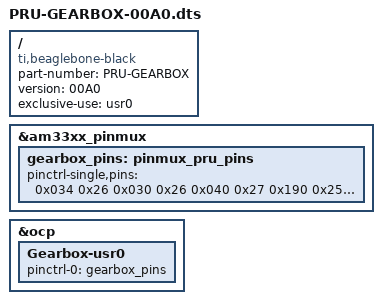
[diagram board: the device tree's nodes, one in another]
 /dts-v1/;  
 /plugin/;  
 
 / {  
   compatible = "ti,beaglebone-black";  
   part-number = "PRU-GEARBOX";  
   version = "00A0";
   exclusive-use =  
//      "P8.11", 
//      "P8.12", 
//      "P9.15", 
//      "P9.31", 
      "usr0";  

   fragment@0 {  
    target = <&am33xx_pinmux>;  
    __overlay__ {  
      gearbox_pins: pinmux_pru_pins {  
       pinctrl-single,pins = <  
	 0x034 0x26  
         0x030 0x26 
	 0x040 0x27
	 0x190 0x25 
	 0x164 0x27
	 0x1A8 0x21
	 0x1b4 0x27
	 0x1AC 0x21
       >;  
      };  
    };  
   };  
   
   fragment@1 {  
    target = <&ocp>;  
    __overlay__ {
        Gearbox-usr0 {  
          status = "okay";  
          pinctrl-names = "default";  
          pinctrl-0 = <&gearbox_pins>;  
      }; 
     }; 
   };  
 };  
